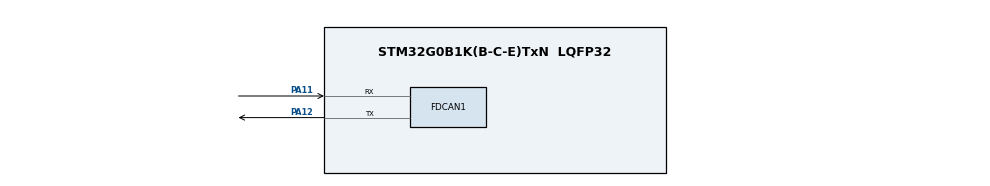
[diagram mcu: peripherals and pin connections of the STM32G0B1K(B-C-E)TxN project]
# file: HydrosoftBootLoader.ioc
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FDCAN1.AutoRetransmission=ENABLE
FDCAN1.DataPrescaler=4
FDCAN1.DataSyncJumpWidth=4
FDCAN1.DataTimeSeg1=11
FDCAN1.DataTimeSeg2=4
FDCAN1.NominalPrescaler=4
FDCAN1.NominalSyncJumpWidth=4
FDCAN1.NominalTimeSeg1=11
FDCAN1.NominalTimeSeg2=4
FDCAN1.StdFiltersNbr=1
Mcu.Family=STM32G0
Mcu.Name=STM32G0B1K(B-C-E)TxN
Mcu.Package=LQFP32
NVIC.TIM16_FDCAN_IT0_IRQn=true\:0\:0\:false\:false\:true\:true\:true
PA11\ [PA9].Mode=FDCAN_Activate
PA11\ [PA9].Signal=FDCAN1_RX
PA12\ [PA10].Mode=FDCAN_Activate
PA12\ [PA10].Signal=FDCAN1_TX
PA13.Mode=Serial_Wire
PA13.Signal=SYS_SWDIO
PA14-BOOT0.Mode=Serial_Wire
PA14-BOOT0.Signal=SYS_SWCLK
ProjectManager.HeapSize=0x200
ProjectManager.StackSize=0x400
ProjectManager.TargetToolchain=STM32CubeIDE
RCC.ADCFreq_Value=64000000
RCC.AHBFreq_Value=64000000
RCC.CortexFreq_Value=64000000
RCC.EXTERNAL_CLOCK_VALUE=48000
RCC.HCLKFreq_Value=64000000
RCC.HSE_VALUE=8000000
RCC.HSI48_VALUE=48000000
RCC.HSI_VALUE=16000000
RCC.LSE_VALUE=32768
RCC.SYSCLKFreq_VALUE=64000000
RCC.SYSCLKSource=RCC_SYSCLKSOURCE_PLLCLK
RCC.USBFreq_Value=48000000
RCC.VCOOutputFreq_Value=128000000
VP_SYS_VS_DBSignals.Mode=DisableDeadBatterySignals
board=custom

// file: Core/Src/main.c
/* USER CODE BEGIN Header */
/**
  ******************************************************************************
  * @file           : main.c
  * @brief          : Main program body
  ******************************************************************************
  * @attention
  *
  * Copyright (c) 2022 STMicroelectronics.
  * All rights reserved.
  *
  * This software is licensed under terms that can be found in the LICENSE file
  * in the root directory of this software component.
  * If no LICENSE file comes with this software, it is provided AS-IS.
  *
  ******************************************************************************
  */
/* USER CODE END Header */
#include "main.h"

/* USER CODE BEGIN Includes */
#include "menu.h"
#include "canbus_if.h"
/* USER CODE END Includes */

FDCAN_HandleTypeDef hfdcan1;

/* USER CODE BEGIN PV */
extern pFunction JumpToApplication;
extern uint32_t JumpAddress;
/* USER CODE END PV */

void SystemClock_Config(void);
static void MX_GPIO_Init(void);
static void MX_FDCAN1_Init(void);
/* USER CODE BEGIN PFP */
void flashBoardID(void);
/* USER CODE END PFP */

int main(void)
{

  /* MCU Configuration--------------------------------------------------------*/

  /* Reset of all peripherals, Initializes the Flash interface and the Systick. */
  HAL_Init();

  /* Configure the system clock */
  SystemClock_Config();

  /* Initialize all configured peripherals */
  MX_GPIO_Init();
  MX_FDCAN1_Init();
  /* USER CODE BEGIN 2 */
  flashBoardID();
  FDCAN_Config();

   IAP_Menu(); //10 000 ms before jump
  /* USER CODE END 2 */

  /* Infinite loop */
  while (1)
  {

  }
}

void SystemClock_Config(void)
{
  LL_FLASH_SetLatency(LL_FLASH_LATENCY_2);
  while(LL_FLASH_GetLatency() != LL_FLASH_LATENCY_2)
  {
  }

  /* HSI configuration and activation */
  LL_RCC_HSI_Enable();
  while(LL_RCC_HSI_IsReady() != 1)
  {
  }

  /* Main PLL configuration and activation */
  LL_RCC_PLL_ConfigDomain_SYS(LL_RCC_PLLSOURCE_HSI, LL_RCC_PLLM_DIV_1, 8, LL_RCC_PLLR_DIV_2);
  LL_RCC_PLL_Enable();
  LL_RCC_PLL_EnableDomain_SYS();
  while(LL_RCC_PLL_IsReady() != 1)
  {
  }

  /* Set AHB prescaler*/
  LL_RCC_SetAHBPrescaler(LL_RCC_SYSCLK_DIV_1);

  /* Sysclk activation on the main PLL */
  LL_RCC_SetSysClkSource(LL_RCC_SYS_CLKSOURCE_PLL);
  while(LL_RCC_GetSysClkSource() != LL_RCC_SYS_CLKSOURCE_STATUS_PLL)
  {
  }

  /* Set APB1 prescaler*/
  LL_RCC_SetAPB1Prescaler(LL_RCC_APB1_DIV_1);
  /* Update CMSIS variable (which can be updated also through SystemCoreClockUpdate function) */
  LL_SetSystemCoreClock(64000000);

   /* Update the time base */
  if (HAL_InitTick (TICK_INT_PRIORITY) != HAL_OK)
  {
    Error_Handler();
  }
}

static void MX_FDCAN1_Init(void)
{

  hfdcan1.Instance = FDCAN1;
  hfdcan1.Init.ClockDivider = FDCAN_CLOCK_DIV1;
  hfdcan1.Init.FrameFormat = FDCAN_FRAME_CLASSIC;
  hfdcan1.Init.Mode = FDCAN_MODE_NORMAL;
  hfdcan1.Init.AutoRetransmission = ENABLE;
  hfdcan1.Init.TransmitPause = DISABLE;
  hfdcan1.Init.ProtocolException = DISABLE;
  hfdcan1.Init.NominalPrescaler = 4;
  hfdcan1.Init.NominalSyncJumpWidth = 4;
  hfdcan1.Init.NominalTimeSeg1 = 11;
  hfdcan1.Init.NominalTimeSeg2 = 4;
  hfdcan1.Init.DataPrescaler = 4;
  hfdcan1.Init.DataSyncJumpWidth = 4;
  hfdcan1.Init.DataTimeSeg1 = 11;
  hfdcan1.Init.DataTimeSeg2 = 4;
  hfdcan1.Init.StdFiltersNbr = 1;
  hfdcan1.Init.ExtFiltersNbr = 0;
  hfdcan1.Init.TxFifoQueueMode = FDCAN_TX_FIFO_OPERATION;
  if (HAL_FDCAN_Init(&hfdcan1) != HAL_OK)
  {
    Error_Handler();
  }

}

static void MX_GPIO_Init(void)
{

  /* GPIO Ports Clock Enable */
  LL_IOP_GRP1_EnableClock(LL_IOP_GRP1_PERIPH_GPIOA);

}

/* USER CODE BEGIN 4 */
/**
 * Flash board infos into the previous page on the flash starting at 0x08003800
 */
void flashBoardID(void){
	extern const uint64_t CAN_ID_64;
	FLASH_If_Erase(FLASH_USER_START_ADDR-FLASH_PAGE_SIZE,FLASH_USER_START_ADDR-1);
	HAL_FLASH_Unlock();
	HAL_FLASH_Program(FLASH_TYPEPROGRAM_DOUBLEWORD, FLASH_USER_START_ADDR-FLASH_PAGE_SIZE, CAN_ID_64);
	HAL_FLASH_Lock();
}
void deInitAll(void){

	  HAL_FDCAN_DeInit(&hfdcan1);
	  LL_IOP_GRP1_DisableClock(LL_IOP_GRP1_PERIPH_GPIOA);//HAL_GPIO_DeInit();

	__HAL_RCC_PWR_CLK_DISABLE();
	HAL_RCC_DeInit();

	HAL_DeInit();

	//HAL_SuspendTick();
	SysTick->CTRL = 0;
	SysTick->LOAD = 0;
	SysTick->VAL = 0;

}
/* USER CODE END 4 */

void Error_Handler(void)
{
  __disable_irq();
  while (1)
  {
  }
}
